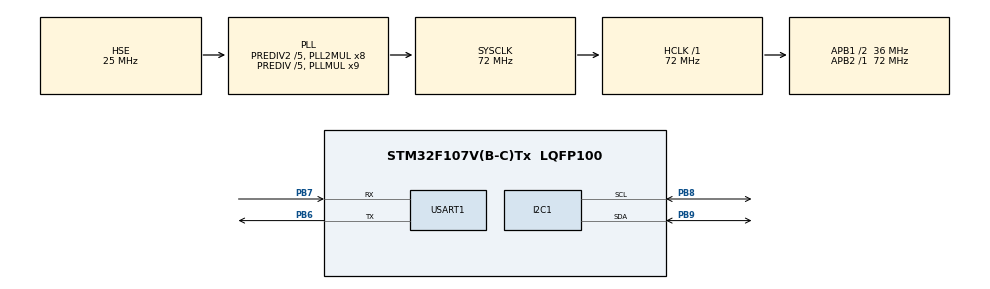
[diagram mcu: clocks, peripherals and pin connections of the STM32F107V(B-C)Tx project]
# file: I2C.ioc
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FREERTOS.Tasks01=defaultTask,24,128,StartDefaultTask,Default,NULL,Dynamic,NULL,NULL
Mcu.Family=STM32F1
Mcu.Name=STM32F107V(B-C)Tx
Mcu.Package=LQFP100
NVIC.I2C1_ER_IRQn=true\:5\:0\:false\:false\:true\:true\:true\:true
NVIC.I2C1_EV_IRQn=true\:5\:0\:false\:false\:true\:true\:true\:true
NVIC.PriorityGroup=NVIC_PRIORITYGROUP_4
NVIC.TIM7_IRQn=true\:0\:0\:false\:false\:true\:false\:false\:true
NVIC.TimeBase=TIM7_IRQn
NVIC.TimeBaseIP=TIM7
OSC_IN.Mode=HSE-External-Oscillator
OSC_IN.Signal=RCC_OSC_IN
OSC_OUT.Mode=HSE-External-Oscillator
OSC_OUT.Signal=RCC_OSC_OUT
PA13.Mode=Serial_Wire
PA13.Signal=SYS_JTMS-SWDIO
PA14.Mode=Serial_Wire
PA14.Signal=SYS_JTCK-SWCLK
PB6.Mode=Asynchronous
PB6.Signal=USART1_TX
PB7.Mode=Asynchronous
PB7.Signal=USART1_RX
PB8.Mode=I2C
PB8.Signal=I2C1_SCL
PB9.Mode=I2C
PB9.Signal=I2C1_SDA
ProjectManager.HeapSize=0x200
ProjectManager.StackSize=0x400
ProjectManager.TargetToolchain=STM32CubeIDE
RCC.AHBFreq_Value=72000000
RCC.APB1CLKDivider=RCC_HCLK_DIV2
RCC.APB1Freq_Value=36000000
RCC.APB1TimFreq_Value=72000000
RCC.APB2Freq_Value=72000000
RCC.APB2TimFreq_Value=72000000
RCC.HCLKFreq_Value=72000000
RCC.HSEDivPLL=RCC_HSE_PREDIV_DIV5
RCC.HSE_VALUE=25000000
RCC.PLLMUL=RCC_PLL_MUL9
RCC.PLLSourceVirtual=RCC_PLLSOURCE_HSE
RCC.Prediv1Source=RCC_PREDIV1_SOURCE_PLL2
RCC.Prediv2=RCC_HSE_PREDIV2_DIV5
RCC.SYSCLKFreq_VALUE=72000000
RCC.SYSCLKSource=RCC_SYSCLKSOURCE_PLLCLK
RCC.USBFreq_Value=48000000
USART1.VirtualMode=VM_ASYNC
VP_FREERTOS_VS_CMSIS_V2.Mode=CMSIS_V2
VP_SYS_VS_tim7.Mode=TIM7
board=custom

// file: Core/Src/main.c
/* USER CODE BEGIN Header */
/**
  ******************************************************************************
  * @file           : main.c
  * @brief          : Main program body
  ******************************************************************************
  * @attention
  *
  * <h2><center>&copy; Copyright (c) 2021 STMicroelectronics.
  * All rights reserved.</center></h2>
  *
  * This software component is licensed by ST under Ultimate Liberty license
  * SLA0044, the "License"; You may not use this file except in compliance with
  * the License. You may obtain a copy of the License at:
  *                             www.st.com/SLA0044
  *
  ******************************************************************************
  */
/* USER CODE END Header */
#include "main.h"
#include "cmsis_os.h"
#include "i2c.h"
#include "usart.h"
#include "gpio.h"

/* USER CODE BEGIN Includes */
#include <stdio.h>
/* USER CODE END Includes */

/* USER CODE BEGIN PM */
#define DEBUG_UART      huart1
/* USER CODE END PM */

void SystemClock_Config(void);
void MX_FREERTOS_Init(void);

/* USER CODE BEGIN 0 */
int __io_putchar(int ch)
{
    uint8_t byte = ch;
    HAL_StatusTypeDef rv = HAL_UART_Transmit(&DEBUG_UART, &byte, 1, 1);
    return rv == HAL_OK ? 1 : 0;
}
/* USER CODE END 0 */

int main(void)
{
  /* USER CODE BEGIN 1 */
    HAL_StatusTypeDef rv;
  /* USER CODE END 1 */

  /* MCU Configuration--------------------------------------------------------*/

  /* Reset of all peripherals, Initializes the Flash interface and the Systick. */
  HAL_Init();

  /* Configure the system clock */
  SystemClock_Config();

  /* Initialize all configured peripherals */
  MX_GPIO_Init();
  MX_I2C1_Init();
  MX_USART1_UART_Init();
  /* USER CODE BEGIN 2 */
  printf("WaveShare Open107V I2C demo\n");
  printf("Hi!\n");
  uint8_t data[8] = {0};
  rv = HAL_I2C_Master_Transmit_IT(&hi2c1, 0xA0, data, 1);
  printf("rv = %d\n", rv);
  /* USER CODE END 2 */

  /* Init scheduler */
  osKernelInitialize();  /* Call init function for freertos objects (in freertos.c) */
  MX_FREERTOS_Init();
  /* Start scheduler */
  osKernelStart();

  /* We should never get here as control is now taken by the scheduler */
  /* Infinite loop */
  while (1)
  {

  }
}

void SystemClock_Config(void)
{
  RCC_OscInitTypeDef RCC_OscInitStruct = {0};
  RCC_ClkInitTypeDef RCC_ClkInitStruct = {0};

  /** Initializes the RCC Oscillators according to the specified parameters
  * in the RCC_OscInitTypeDef structure.
  */
  RCC_OscInitStruct.OscillatorType = RCC_OSCILLATORTYPE_HSE;
  RCC_OscInitStruct.HSEState = RCC_HSE_ON;
  RCC_OscInitStruct.HSEPredivValue = RCC_HSE_PREDIV_DIV5;
  RCC_OscInitStruct.HSIState = RCC_HSI_ON;
  RCC_OscInitStruct.Prediv1Source = RCC_PREDIV1_SOURCE_PLL2;
  RCC_OscInitStruct.PLL.PLLState = RCC_PLL_ON;
  RCC_OscInitStruct.PLL.PLLSource = RCC_PLLSOURCE_HSE;
  RCC_OscInitStruct.PLL.PLLMUL = RCC_PLL_MUL9;
  RCC_OscInitStruct.PLL2.PLL2State = RCC_PLL2_ON;
  RCC_OscInitStruct.PLL2.PLL2MUL = RCC_PLL2_MUL8;
  RCC_OscInitStruct.PLL2.HSEPrediv2Value = RCC_HSE_PREDIV2_DIV5;
  if (HAL_RCC_OscConfig(&RCC_OscInitStruct) != HAL_OK)
  {
    Error_Handler();
  }
  /** Initializes the CPU, AHB and APB buses clocks
  */
  RCC_ClkInitStruct.ClockType = RCC_CLOCKTYPE_HCLK|RCC_CLOCKTYPE_SYSCLK
                              |RCC_CLOCKTYPE_PCLK1|RCC_CLOCKTYPE_PCLK2;
  RCC_ClkInitStruct.SYSCLKSource = RCC_SYSCLKSOURCE_PLLCLK;
  RCC_ClkInitStruct.AHBCLKDivider = RCC_SYSCLK_DIV1;
  RCC_ClkInitStruct.APB1CLKDivider = RCC_HCLK_DIV2;
  RCC_ClkInitStruct.APB2CLKDivider = RCC_HCLK_DIV1;

  if (HAL_RCC_ClockConfig(&RCC_ClkInitStruct, FLASH_LATENCY_2) != HAL_OK)
  {
    Error_Handler();
  }
  /** Configure the Systick interrupt time
  */
  __HAL_RCC_PLLI2S_ENABLE();
}

/* USER CODE BEGIN 4 */
void HAL_I2C_MasterTxCpltCallback(I2C_HandleTypeDef *hi2c)
{
    printf("Done!\n");
}
/* USER CODE END 4 */

 /**
  * @brief  Period elapsed callback in non blocking mode
  * @note   This function is called  when TIM7 interrupt took place, inside
  * HAL_TIM_IRQHandler(). It makes a direct call to HAL_IncTick() to increment
  * a global variable "uwTick" used as application time base.
  * @param  htim : TIM handle
  * @retval None
  */
void HAL_TIM_PeriodElapsedCallback(TIM_HandleTypeDef *htim)
{
  if (htim->Instance == TIM7) {
    HAL_IncTick();
  }
}

void Error_Handler(void)
{
  __disable_irq();
  while (1)
  {
  }
}

/************************ (C) COPYRIGHT STMicroelectronics *****END OF FILE****/
